# APM32F446 register map
File version: 1.0
CPU: CM4 r0p1, little endian, MPU, FPU, 4 interrupt priority bits
Registers are 32-bit, read-write, reset 0x0 unless marked. A register's access mark holds for its fields unless they carry their own. Offsets are from the block's base; [hi:lo] are bit positions; {n}, {i} and the like mark numbered series; 'fields as' and 'values as' point back to an identical list.

## SIM — System Integration Management
Base 0x40048000
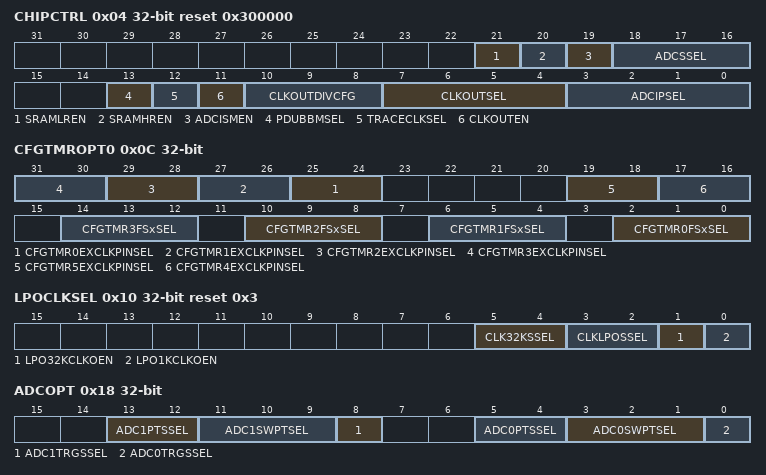
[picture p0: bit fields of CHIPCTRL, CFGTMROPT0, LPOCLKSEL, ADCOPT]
0x04 CHIPCTRL reset 0x300000 — Chip Control register
  [21] SRAMLREN — SRAML Retention Enable
    0=SRAML contents are retained across resets; 1=No SRAML retention
  [20] SRAMHREN — SRAMU Retention Enable
    0=SRAMU contents are retained across resets; 1=No SRAMU retention
  [19] ADCISMEN — ADC Internal Supply Monitoring Enable
    0=Disable internal supply monitoring; 1=Enable internal supply monitoring
  [18:16] ADCSSEL — ADC Supply Select
    0=5 V input VDD supply (VDD); 1=5 V input analog supply (VDDA); 2=ADC Reference Supply (VREFH); 3=3.3 V Oscillator Regulator Output (VDD_3V); 4=3.3 V flash regulator output (VDD_flash_3V); 5=1.2 V core regulator output (VDD_LV)
  [13] PDUBBMSEL — PDU Back-to-Back Mode Select
    0=PDU0 channel 0 back-to-back operation with ADC0 CCFLG[7:0] and PDU1 channel 0 back-to-back operation with ADC1 CCFLG[7:0]; 1=Channel 0 of PDU0 and PDU1 back-to-back operation with CCFLG[7:0] of ADC0 and ADC1
  [12] TRACECLKSEL — Trace Clock Source Select
    0=Core clock; 1=Platform clock
  [11] CLKOUTEN — Clock Output Enable
    0=Clockout disable; 1=Clockout enable
  [10:8] CLKOUTDIVCFG — Clock Output Divide Ratio Configure
    {v}=Divide by {v+1} (v=0..7)
  [7:4] CLKOUTSEL — Clock Output Select
    0=SCG CLKOUT; 2=SYSOSC DIV2 CLK; 4=LSICLK DIV2 CLK; 5=QSPI SFIF_CLK_HYP: Divide by 2 clock (configured through SCLKCONFIG[5]) for HyperRAM going to sfif clock to QSPI; For others: Reserved; 6=HSICLK DIV2 CLK; 7=HCLK; 8=SYSPLL DIV2 CLK; 9=BUS_CLK; 10=LPO128K_CLK; 11=QSPI IPG_CLK; For others: Reserved; 12=LPO_CLK as selected by SIM_LPOCLKS[LPOCLKSEL]; 13=QSPI IPG_CLK_SFIF; For others: Reserved; 14=RTC_CLK as selected by SIM_LPOCLKS[RTCCLKSEL]; 15=QSPI IPG_CLK_2XSFIF; For others: Reserved
  [3:0] ADCIPSEL — ADC Interleave Pins Select
    0=Interleaving disabled. No channel pair interleaved. Interleaved channels are individually connected to pins. PTC0 is connected to ADC0_SE8. PTC1 is connected to ADC0_SE9. PTB15 is connected to ADC1_SE14. PTB16 is connected to ADC1_SE15. PTB0 is connected to ADC0_SE4. PTB1 is connected to ADC0_SE5. PTB13 is connected to ADC1_SE8. PTB14 is connected to ADC1_SE9.; 0b1xxx=PTB14 to ADC1_SE9 and ADC0_SE9; 0bx1xx=PTB13 to ADC1_SE8 and ADC0_SE8; 0bxx1x=PTB1 to ADC0_SE5 and ADC1_SE15; 0bxxx1=PTB0 to ADC0_SE4 and ADC1_SE14
0x0C CFGTMROPT0 — CFGTMR Option Register 0
  [2n+25:2n+24] CFGTMR{n}EXCLKPINSEL (n=0..3) — CFGTMR{n} External Clock Pin Select
    0=CFGTMR{n} external clock driven by TCLK0 pin; 1=CFGTMR{n} external clock driven by TCLK1 pin; 2=CFGTMR{n} external clock driven by TCLK2 pin; 3=No clock input
  [19:18] CFGTMR5EXCLKPINSEL — CFGTMR5 External Clock Pin Select
    0=CFGTMR5 external clock driven by TCLK0 pin; 1=CFGTMR5 external clock driven by TCLK1 pin; 2=CFGTMR5 external clock driven by TCLK2 pin; 3=No clock input
  [17:16] CFGTMR4EXCLKPINSEL — CFGTMR4 External Clock Pin Select
    0=CFGTMR4 external clock driven by TCLK0 pin; 1=CFGTMR4 external clock driven by TCLK1 pin; 2=CFGTMR4 external clock driven by TCLK2 pin; 3=No clock input
  [4n+2:4n] CFGTMR{n}FSxSEL (n=0..3) — CFGTMR{n} Fault Source x Select
    0=CFGTMR{n}_FLTx pin; 1=TMC_CFGTMR{n} out
0x10 LPOCLKSEL reset 0x3 — LPO Clock Select Register
  [5:4] CLK32KSSEL — Peripherals 32 kHz Clock Source Select
    0=SYSOSCDIV1_CLK; 1=32 kHz LPO_CLK; 2=RTC_CLKIN clock; 3=HSICLKDIV1_CLK
  [3:2] CLKLPOSSEL — Peripherals LPO Clock Source Select
    0=128 kHz LPO_CLK; 1=No clock; 2=32 kHz LPO_CLK which is derived from the 128 kHz LPO_CLK; 3=1 kHz LPO_CLK which is derived from the 128 kHz LPO_CLK
  [1] LPO32KCLKOEN — 32 kHz LPOCLK Output Enable
    0=Disable 32 kHz LPO_CLK output; 1=Enable 32 kHz LPO_CLK output
  [0] LPO1KCLKOEN — 1 kHz LPOCLK Output Enable
    0=Disable 1 kHz LPO_CLK output; 1=Enable 1 kHz LPO_CLK output
0x18 ADCOPT — ADC Options Register
  [13:12] ADC1PTSSEL — ADC1 Pretrigger Source Select
    0=PDU pretrigger (default); 1=TMC pretrigger; 2=Software pretrigger
  [11:9] ADC1SWPTSEL — ADC1 Software Pretrigger Sources Select
    0=Software pretrigger disabled; {v}=Software pretrigger {v-4} (v=4..7)
  [8] ADC1TRGSSEL — ADC1 Trigger Source Select
    0=PDU output; 1=TMC output
  [5:4] ADC0PTSSEL — ADC0 Pretrigger Source Select
    values as ADC1PTSSEL
  [3:1] ADC0SWPTSEL — ADC0 Software Pretrigger Sources Select
    values as ADC1SWPTSEL
  [0] ADC0TRGSSEL — ADC0 Trigger Source Select
    0=PDU output; 1=TMC output
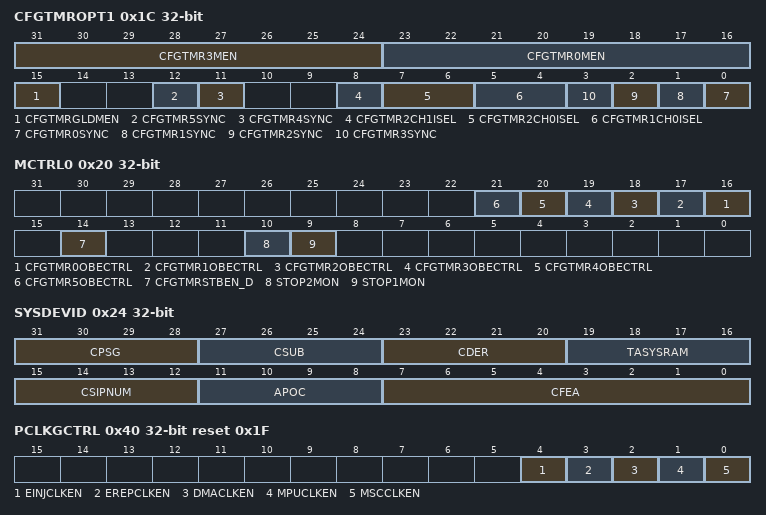
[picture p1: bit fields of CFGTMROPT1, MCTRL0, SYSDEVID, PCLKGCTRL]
0x1C CFGTMROPT1 — CFGTMR Option Register 1
  [31:24] CFGTMR3MEN — CFGTMR3 Modulation with CFGTMR2_CH1 Enable
    0=No modulation with CFGTMR2_CH1; 1=Modulation with CFGTMR2_CH1
  [23:16] CFGTMR0MEN — CFGTMR0 Modulation with CFGTMR1_CH1 Enable
    0=No modulation with CFGTMR1_CH1; 1=Modulation with CFGTMR1_CH1
  [15] CFGTMRGLDMEN — CFGTMR Global Load Mechanism Enable
    0=CFGTMR Global load mechanism disabled; 1=CFGTMR Global load mechanism enabled
  [12] CFGTMR5SYNC — CFGTMR5 Synchronization
  [11] CFGTMR4SYNC — CFGTMR4 Synchronization
  [8] CFGTMR2CH1ISEL — CFGTMR2 CH1 Input Select
    0=CFGTMR2_CH1 input; 1=exclusive OR of CFGTMR2_CH0,CFGTMR2_CH1,and CFGTMR1_CH1
  [7:6] CFGTMR2CH0ISEL — CFGTMR2 CH1 Input Select
    0=CFGTMR2_CH0 input; 1=CMP0 output
  [5:4] CFGTMR1CH0ISEL — CFGTMR1 CH0 Input Select
    0=CFGTMR1_CH0 input; 1=CMP0 output
  [n] CFGTMR{n}SYNC (n=0..3) — CFGTMR{n} Synchronization
0x20 MCTRL0 — Miscellaneous control register 0
  [n+16] CFGTMR{n}OBECTRL (n=0..5) — CFGTMR{n} OBE Control
    0=The CFGTMR channel output is put to safe state when the CFGTMR counter is enabled and the CFGTMR channel output is enabled by Fault Control (CFGTMR_FMSEL[FCTRLMSEL]!=2'b00 and CFGTMR_FCTRL[FEOSTS]=1'b0) and PWM is enabled (CFGTMR_CSTS[PWMOENCHn] = 1'b1). Otherwise the channel output is tristated.; 1=The CFGTMR channel output state is retained when the channel is in output mode. The output channel is tristated when the channel is in input capture [DECMEN=1'b0, CHCM=1'b0, MSnB:MSnA=2'b00] or dual edge capture mode [DECMEN=1'b1].
  [14] CFGTMRSTBEN_D — CFGTMR Split Time Base Enable/Disable
    0=All the CFGTMRs have a single global time-base; 1=CFGTMR0-3 have a common time-base and others have a different common time-base
  [10] STOP2MON — STOP2 Monitor
    0=System clock enabled or STOP2 entry aborted; 1=STOP2 entry successful
  [9] STOP1MON — STOP1 Monitor
    0=Bus clock enabled or STOP1 entry aborted; 1=STOP1 entry successful
0x24 SYSDEVID ro reset not defined — System Device Identification Register
  [31:28] CPSG — Chip Product Series Generation
  [27:24] CSUB — Chip Subseries
  [23:20] CDER — Chip Derivate
  [19:16] TASYSRAM — Total Available System RAM
  [15:12] CSIPNUM — Chip Silicon Implementation Number
  [11:8] APOC — Available Package Options for Chips
    2=48 LQFP; 3=64 LQFP; 4=100 LQFP; 6=144 LQFP; 7=176 LQFP; 8=100 MAP BGA
  [7:0] CFEA — Chip Features
0x40 PCLKGCTRL reset 0x1F — Platform Clock Gating Control Register
  [all] fields
    0=Clock disabled; 1=Clock enabled
  [4] EINJCLKEN — EINJ Clock Enable
  [3] EREPCLKEN — EREP Clock Enable
  [2] DMACLKEN — DMA Clock Gating Control
  [1] MPUCLKEN — MPU Clock Enable
  [0] MSCCLKEN — MSC Clock Enable
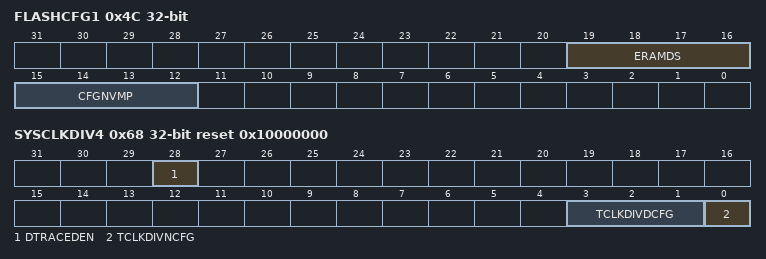
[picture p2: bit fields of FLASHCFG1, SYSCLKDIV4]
0x4C FLASHCFG1 reset not defined — Flash Configure Register 1
  [19:16] ERAMDS ro — EEPROM SRAM Data Size
    2=4 KB; 3=2 KB; 4=1 KB; 5=512 Bytes; 6=256 Bytes; 7=128 Bytes; 8=64 Bytes; 9=32 Bytes; 15=0 Bytes
  [15:12] CFGNVMP ro — Configurable NVM Partition
0x54 UID127_96 ro reset not defined — Unique Identification127_96 Register
  [31:0] CUID96TO127 — Chip Unique Identification127_96
0x58 UID95_64 ro reset not defined — Unique Identification95_64Register
  [31:0] CUID64TO95 — Chip Unique Identification95_64
0x5C UID63_32 ro reset not defined — Unique Identification63_32Register
  [31:0] CUID32TO63 — Chip Unique Identification63_32
0x60 UID31_0 ro reset not defined — Unique Identification31_0Register
  [31:0] CUID0TO31 — Chip Unique Identification31_0
0x68 SYSCLKDIV4 reset 0x10000000 — System Clock Divider Register 4
  [28] DTRACEDEN — Debug Trace Divider Enable
    0=Debug trace divider disabled; 1=Debug trace divider enabled
  [3:1] TCLKDIVDCFG — Trace Fractional Clock Division Denominator Factor Configure
  [0] TCLKDIVNCFG — Trace Fractional Clock Division Numerator Factor Configure
0x6C MCTRL1 — Miscellaneous Control register 1
  [0] TMC_PSWTR — TMC Peripheral Software Trigger
